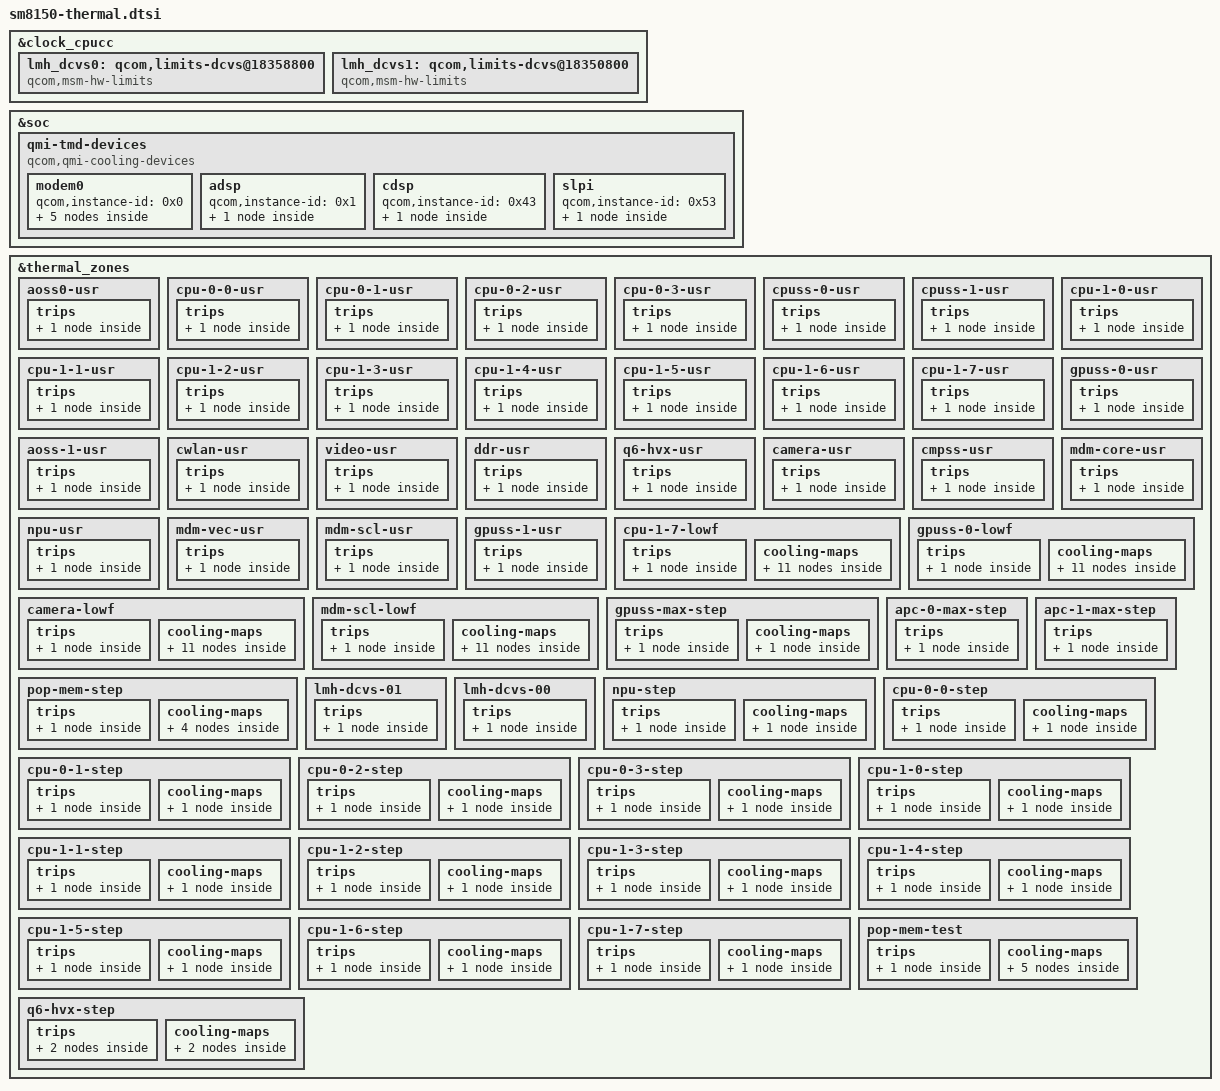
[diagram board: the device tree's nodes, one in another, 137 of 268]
/* Copyright (c) 2018, The Linux Foundation. All rights reserved.
 *
 * This program is free software; you can redistribute it and/or modify
 * it under the terms of the GNU General Public License version 2 and
 * only version 2 as published by the Free Software Foundation.
 *
 * This program is distributed in the hope that it will be useful,
 * but WITHOUT ANY WARRANTY; without even the implied warranty of
 * MERCHANTABILITY or FITNESS FOR A PARTICULAR PURPOSE.  See the
 * GNU General Public License for more details.
 */

#include <dt-bindings/thermal/thermal.h>

&clock_cpucc {
	#address-cells = <1>;
	#size-cells = <1>;
	lmh_dcvs0: qcom,limits-dcvs@18358800 {
		compatible = "qcom,msm-hw-limits";
		interrupts = <GIC_SPI 32 IRQ_TYPE_LEVEL_HIGH>;
		qcom,affinity = <0>;
		reg = <0x18358800 0x1000>,
			<0x18323000 0x1000>;
		#thermal-sensor-cells = <0>;
	};

	lmh_dcvs1: qcom,limits-dcvs@18350800 {
		compatible = "qcom,msm-hw-limits";
		interrupts = <GIC_SPI 33 IRQ_TYPE_LEVEL_HIGH>;
		qcom,affinity = <1>;
		reg = <0x18350800 0x1000>,
			<0x18325800 0x1000>;
		#thermal-sensor-cells = <0>;
		isens_vref_0p8-supply = <&pm8150_l5_ao>;
		isens-vref-0p8-settings = <880000 880000 20000>;
		isens_vref_1p8-supply = <&pm8150_l12_ao>;
		isens-vref-1p8-settings = <1800000 1800000 20000>;
	};
};

&soc {
	qmi-tmd-devices {
		compatible = "qcom,qmi-cooling-devices";

		modem0 {
			qcom,instance-id = <0x0>;

			modem0_pa: modem0_pa {
				qcom,qmi-dev-name = "pa";
				#cooling-cells = <2>;
			};

			modem0_proc: modem0_proc {
				qcom,qmi-dev-name = "modem";
				#cooling-cells = <2>;
			};

			modem0_current: modem0_current {
				qcom,qmi-dev-name = "modem_current";
				#cooling-cells = <2>;
			};

			modem0_skin: modem0_skin {
				qcom,qmi-dev-name = "modem_skin";
				#cooling-cells = <2>;
			};

			modem0_vdd: modem0_vdd {
				qcom,qmi-dev-name = "cpuv_restriction_cold";
				#cooling-cells = <2>;
			};
		};

		adsp {
			qcom,instance-id = <0x1>;

			adsp_vdd: adsp_vdd {
				qcom,qmi-dev-name = "cpuv_restriction_cold";
				#cooling-cells = <2>;
			};
		};

		cdsp {
			qcom,instance-id = <0x43>;

			cdsp_vdd: cdsp_vdd {
				qcom,qmi-dev-name = "cpuv_restriction_cold";
				#cooling-cells = <2>;
			};
		};

		slpi {
			qcom,instance-id = <0x53>;

			slpi_vdd: slpi_vdd {
				qcom,qmi-dev-name = "cpuv_restriction_cold";
				#cooling-cells = <2>;
			};
		};
	};
};

&thermal_zones {
	aoss0-usr {
		polling-delay-passive = <0>;
		polling-delay = <0>;
		thermal-governor = "user_space";
		thermal-sensors = <&tsens0 0>;
		trips {
			active-config0 {
				temperature = <125000>;
				hysteresis = <1000>;
				type = "passive";
			};
		};
	};

	cpu-0-0-usr {
		polling-delay-passive = <0>;
		polling-delay = <0>;
		thermal-governor = "user_space";
		thermal-sensors = <&tsens0 1>;
		trips {
			active-config0 {
				temperature = <125000>;
				hysteresis = <1000>;
				type = "passive";
			};
		};
	};

	cpu-0-1-usr {
		polling-delay-passive = <0>;
		polling-delay = <0>;
		thermal-governor = "user_space";
		thermal-sensors = <&tsens0 2>;
		trips {
			active-config0 {
				temperature = <125000>;
				hysteresis = <1000>;
				type = "passive";
			};
		};
	};

	cpu-0-2-usr {
		polling-delay-passive = <0>;
		polling-delay = <0>;
		thermal-governor = "user_space";
		thermal-sensors = <&tsens0 3>;
		trips {
			active-config0 {
				temperature = <125000>;
				hysteresis = <1000>;
				type = "passive";
			};
		};
	};

	cpu-0-3-usr {
		polling-delay-passive = <0>;
		polling-delay = <0>;
		thermal-sensors = <&tsens0 4>;
		thermal-governor = "user_space";
		trips {
			active-config0 {
				temperature = <125000>;
				hysteresis = <1000>;
				type = "passive";
			};
		};
	};

	cpuss-0-usr {
		polling-delay-passive = <0>;
		polling-delay = <0>;
		thermal-sensors = <&tsens0 5>;
		thermal-governor = "user_space";
		trips {
			active-config0 {
				temperature = <125000>;
				hysteresis = <1000>;
				type = "passive";
			};
		};
	};

	cpuss-1-usr {
		polling-delay-passive = <0>;
		polling-delay = <0>;
		thermal-sensors = <&tsens0 6>;
		thermal-governor = "user_space";
		trips {
			active-config0 {
				temperature = <125000>;
				hysteresis = <1000>;
				type = "passive";
			};
		};
	};

	cpu-1-0-usr {
		polling-delay-passive = <0>;
		polling-delay = <0>;
		thermal-sensors = <&tsens0 7>;
		thermal-governor = "user_space";
		trips {
			active-config0 {
				temperature = <125000>;
				hysteresis = <1000>;
				type = "passive";
			};
		};
	};

	cpu-1-1-usr {
		polling-delay-passive = <0>;
		polling-delay = <0>;
		thermal-sensors = <&tsens0 8>;
		thermal-governor = "user_space";
		trips {
			active-config0 {
				temperature = <125000>;
				hysteresis = <1000>;
				type = "passive";
			};
		};
	};

	cpu-1-2-usr {
		polling-delay-passive = <0>;
		polling-delay = <0>;
		thermal-sensors = <&tsens0 9>;
		thermal-governor = "user_space";
		trips {
			active-config0 {
				temperature = <125000>;
				hysteresis = <1000>;
				type = "passive";
			};
		};
	};

	cpu-1-3-usr {
		polling-delay-passive = <0>;
		polling-delay = <0>;
		thermal-sensors = <&tsens0 10>;
		thermal-governor = "user_space";
		trips {
			active-config0 {
				temperature = <125000>;
				hysteresis = <1000>;
				type = "passive";
			};
		};
	};

	cpu-1-4-usr {
		polling-delay-passive = <0>;
		polling-delay = <0>;
		thermal-sensors = <&tsens0 11>;
		thermal-governor = "user_space";
		trips {
			active-config0 {
				temperature = <125000>;
				hysteresis = <1000>;
				type = "passive";
			};
		};
	};

	cpu-1-5-usr {
		polling-delay-passive = <0>;
		polling-delay = <0>;
		thermal-sensors = <&tsens0 12>;
		thermal-governor = "user_space";
		trips {
			active-config0 {
				temperature = <125000>;
				hysteresis = <1000>;
				type = "passive";
			};
		};
	};

	cpu-1-6-usr {
		polling-delay-passive = <0>;
		polling-delay = <0>;
		thermal-sensors = <&tsens0 13>;
		thermal-governor = "user_space";
		trips {
			active-config0 {
				temperature = <125000>;
				hysteresis = <1000>;
				type = "passive";
			};
		};
	};

	cpu-1-7-usr {
		polling-delay-passive = <0>;
		polling-delay = <0>;
		thermal-sensors = <&tsens0 14>;
		thermal-governor = "user_space";
		trips {
			active-config0 {
				temperature = <125000>;
				hysteresis = <1000>;
				type = "passive";
			};
		};
	};

	gpuss-0-usr {
		polling-delay-passive = <0>;
		polling-delay = <0>;
		thermal-sensors = <&tsens0 15>;
		thermal-governor = "user_space";
		trips {
			active-config0 {
				temperature = <125000>;
				hysteresis = <1000>;
				type = "passive";
			};
		};
	};

	aoss-1-usr {
		polling-delay-passive = <0>;
		polling-delay = <0>;
		thermal-sensors = <&tsens1 0>;
		thermal-governor = "user_space";
		trips {
			active-config0 {
				temperature = <125000>;
				hysteresis = <1000>;
				type = "passive";
			};
		};
	};

	cwlan-usr {
		polling-delay-passive = <0>;
		polling-delay = <0>;
		thermal-sensors = <&tsens1 1>;
		thermal-governor = "user_space";
		trips {
			active-config0 {
				temperature = <125000>;
				hysteresis = <1000>;
				type = "passive";
			};
		};
	};

	video-usr {
		polling-delay-passive = <0>;
		polling-delay = <0>;
		thermal-sensors = <&tsens1 2>;
		thermal-governor = "user_space";
		trips {
			active-config0 {
				temperature = <125000>;
				hysteresis = <1000>;
				type = "passive";
			};
		};
	};

	ddr-usr {
		polling-delay-passive = <0>;
		polling-delay = <0>;
		thermal-sensors = <&tsens1 3>;
		thermal-governor = "user_space";
		trips {
			active-config0 {
				temperature = <125000>;
				hysteresis = <1000>;
				type = "passive";
			};
		};
	};

	q6-hvx-usr {
		polling-delay-passive = <0>;
		polling-delay = <0>;
		thermal-sensors = <&tsens1 4>;
		thermal-governor = "user_space";
		trips {
			active-config0 {
				temperature = <125000>;
				hysteresis = <1000>;
				type = "passive";
			};
		};
	};

	camera-usr {
		polling-delay-passive = <0>;
		polling-delay = <0>;
		thermal-sensors = <&tsens1 5>;
		thermal-governor = "user_space";
		trips {
			active-config0 {
				temperature = <125000>;
				hysteresis = <1000>;
				type = "passive";
			};
		};
	};

	cmpss-usr {
		polling-delay-passive = <0>;
		polling-delay = <0>;
		thermal-sensors = <&tsens1 6>;
		thermal-governor = "user_space";
		trips {
			active-config0 {
				temperature = <125000>;
				hysteresis = <1000>;
				type = "passive";
			};
		};
	};

	mdm-core-usr {
		polling-delay-passive = <0>;
		polling-delay = <0>;
		thermal-sensors = <&tsens1 7>;
		thermal-governor = "user_space";
		trips {
			active-config0 {
				temperature = <125000>;
				hysteresis = <1000>;
				type = "passive";
			};
		};
	};

	npu-usr {
		polling-delay-passive = <0>;
		polling-delay = <0>;
		thermal-sensors = <&tsens1 8>;
		thermal-governor = "user_space";
		trips {
			active-config0 {
				temperature = <125000>;
				hysteresis = <1000>;
				type = "passive";
			};
		};
	};

	mdm-vec-usr {
		polling-delay-passive = <0>;
		polling-delay = <0>;
		thermal-sensors = <&tsens1 9>;
		thermal-governor = "user_space";
		trips {
			active-config0 {
				temperature = <125000>;
				hysteresis = <1000>;
				type = "passive";
			};
		};
	};

	mdm-scl-usr {
		polling-delay-passive = <0>;
		polling-delay = <0>;
		thermal-sensors = <&tsens1 10>;
		thermal-governor = "user_space";
		trips {
			active-config0 {
				temperature = <125000>;
				hysteresis = <1000>;
				type = "passive";
			};
		};
	};

	gpuss-1-usr {
		polling-delay-passive = <0>;
		polling-delay = <0>;
		thermal-governor = "user_space";
		thermal-sensors = <&tsens1 11>;
		trips {
			active-config0 {
				temperature = <125000>;
				hysteresis = <1000>;
				type = "passive";
			};
		};
	};

	cpu-1-7-lowf {
		polling-delay-passive = <0>;
		polling-delay = <0>;
		thermal-sensors = <&tsens0 14>;
		thermal-governor = "low_limits_floor";
		tracks-low;
		trips {
			cpu17_trip: cpu17-trip {
				temperature = <5000>;
				hysteresis = <5000>;
				type = "passive";
			};
		};
		cooling-maps {
			cpu0_cdev {
				trip = <&cpu17_trip>;
				cooling-device = <&CPU0 1 1>;
			};
			cpu1_cdev {
				trip = <&cpu17_trip>;
				cooling-device = <&CPU4 5 5>;
			};
			cx_vdd_cdev {
				trip = <&cpu17_trip>;
				cooling-device = <&cx_cdev 0 0>;
			};
			mx_vdd_cdev {
				trip = <&cpu17_trip>;
				cooling-device = <&mx_cdev 0 0>;
			};
			ebi_vdd_cdev {
				trip = <&cpu17_trip>;
				cooling-device = <&ebi_cdev 0 0>;
			};
			mmcx_vdd_cdev {
				trip = <&cpu17_trip>;
				cooling-device = <&mm_cx_cdev 0 0>;
			};
			modem_vdd_cdev {
				trip = <&cpu17_trip>;
				cooling-device = <&modem0_vdd 0 0>;
			};
			adsp_vdd_cdev {
				trip = <&cpu17_trip>;
				cooling-device = <&adsp_vdd 0 0>;
			};
			cdsp_vdd_cdev {
				trip = <&cpu17_trip>;
				cooling-device = <&cdsp_vdd 0 0>;
			};
			slpi_vdd_cdev {
				trip = <&cpu17_trip>;
				cooling-device = <&slpi_vdd 0 0>;
			};
			gpu_vdd_cdev {
				trip = <&cpu17_trip>;
				cooling-device = <&msm_gpu (THERMAL_MAX_LIMIT-2)
							(THERMAL_MAX_LIMIT-2)>;
			};
		};
	};

	gpuss-0-lowf {
		polling-delay-passive = <0>;
		polling-delay = <0>;
		thermal-sensors = <&tsens0 15>;
		thermal-governor = "low_limits_floor";
		tracks-low;
		trips {
			gpuss0_trip: gpuss0-trip {
				temperature = <5000>;
				hysteresis = <5000>;
				type = "passive";
			};
		};
		cooling-maps {
			cpu0_cdev {
				trip = <&gpuss0_trip>;
				cooling-device = <&CPU0 1 1>;
			};
			cpu1_cdev {
				trip = <&gpuss0_trip>;
				cooling-device = <&CPU4 5 5>;
			};
			cx_vdd_cdev {
				trip = <&gpuss0_trip>;
				cooling-device = <&cx_cdev 0 0>;
			};
			mx_vdd_cdev {
				trip = <&gpuss0_trip>;
				cooling-device = <&mx_cdev 0 0>;
			};
			ebi_vdd_cdev {
				trip = <&gpuss0_trip>;
				cooling-device = <&ebi_cdev 0 0>;
			};
			mmcx_vdd_cdev {
				trip = <&gpuss0_trip>;
				cooling-device = <&mm_cx_cdev 0 0>;
			};
			modem_vdd_cdev {
				trip = <&gpuss0_trip>;
				cooling-device = <&modem0_vdd 0 0>;
			};
			adsp_vdd_cdev {
				trip = <&gpuss0_trip>;
				cooling-device = <&adsp_vdd 0 0>;
			};
			cdsp_vdd_cdev {
				trip = <&gpuss0_trip>;
				cooling-device = <&cdsp_vdd 0 0>;
			};
			slpi_vdd_cdev {
				trip = <&gpuss0_trip>;
				cooling-device = <&slpi_vdd 0 0>;
			};
			gpu_vdd_cdev {
				trip = <&gpuss0_trip>;
				cooling-device = <&msm_gpu (THERMAL_MAX_LIMIT-2)
							(THERMAL_MAX_LIMIT-2)>;
			};
		};
	};

	camera-lowf {
		polling-delay-passive = <0>;
		polling-delay = <0>;
		thermal-sensors = <&tsens1 5>;
		thermal-governor = "low_limits_floor";
		tracks-low;
		trips {
			camera_trip: camera-trip {
				temperature = <5000>;
				hysteresis = <5000>;
				type = "passive";
			};
		};
		cooling-maps {
			cpu0_cdev {
				trip = <&camera_trip>;
				cooling-device = <&CPU0 1 1>;
			};
			cpu1_cdev {
				trip = <&camera_trip>;
				cooling-device = <&CPU4 5 5>;
			};
			cx_vdd_cdev {
				trip = <&camera_trip>;
				cooling-device = <&cx_cdev 0 0>;
			};
			mx_vdd_cdev {
				trip = <&camera_trip>;
				cooling-device = <&mx_cdev 0 0>;
			};
			ebi_vdd_cdev {
				trip = <&camera_trip>;
				cooling-device = <&ebi_cdev 0 0>;
			};
			mmcx_vdd_cdev {
				trip = <&camera_trip>;
				cooling-device = <&mm_cx_cdev 0 0>;
			};
			modem_vdd_cdev {
				trip = <&camera_trip>;
				cooling-device = <&modem0_vdd 0 0>;
			};
			adsp_vdd_cdev {
				trip = <&camera_trip>;
				cooling-device = <&adsp_vdd 0 0>;
			};
			cdsp_vdd_cdev {
				trip = <&camera_trip>;
				cooling-device = <&cdsp_vdd 0 0>;
			};
			slpi_vdd_cdev {
				trip = <&camera_trip>;
				cooling-device = <&slpi_vdd 0 0>;
			};
			gpu_vdd_cdev {
				trip = <&camera_trip>;
				cooling-device = <&msm_gpu (THERMAL_MAX_LIMIT-2)
							(THERMAL_MAX_LIMIT-2)>;
			};
		};
	};

	mdm-scl-lowf {
		polling-delay-passive = <0>;
		polling-delay = <0>;
		thermal-sensors = <&tsens1 10>;
		thermal-governor = "low_limits_floor";
		tracks-low;
		trips {
			mdms_trip: mdms-trip {
				temperature = <5000>;
				hysteresis = <5000>;
				type = "passive";
			};
		};
		cooling-maps {
			cpu0_cdev {
				trip = <&mdms_trip>;
				cooling-device = <&CPU0 1 1>;
			};
			cpu1_cdev {
				trip = <&mdms_trip>;
				cooling-device = <&CPU4 5 5>;
			};
			cx_vdd_cdev {
				trip = <&mdms_trip>;
				cooling-device = <&cx_cdev 0 0>;
			};
			mx_vdd_cdev {
				trip = <&mdms_trip>;
				cooling-device = <&mx_cdev 0 0>;
			};
			ebi_vdd_cdev {
				trip = <&mdms_trip>;
				cooling-device = <&ebi_cdev 0 0>;
			};
			mmcx_vdd_cdev {
				trip = <&mdms_trip>;
				cooling-device = <&mm_cx_cdev 0 0>;
			};
			modem_vdd_cdev {
				trip = <&mdms_trip>;
				cooling-device = <&modem0_vdd 0 0>;
			};
			adsp_vdd_cdev {
				trip = <&mdms_trip>;
				cooling-device = <&adsp_vdd 0 0>;
			};
			cdsp_vdd_cdev {
				trip = <&mdms_trip>;
				cooling-device = <&cdsp_vdd 0 0>;
			};
			slpi_vdd_cdev {
				trip = <&mdms_trip>;
				cooling-device = <&slpi_vdd 0 0>;
			};
			gpu_vdd_cdev {
				trip = <&mdms_trip>;
				cooling-device = <&msm_gpu (THERMAL_MAX_LIMIT-2)
							(THERMAL_MAX_LIMIT-2)>;
			};
		};
	};

	gpuss-max-step {
		polling-delay-passive = <10>;
		polling-delay = <100>;
		thermal-governor = "step_wise";
		trips {
			gpu_trip0: gpu-trip0 {
				temperature = <95000>;
				hysteresis = <0>;
				type = "passive";
			};
		};
		cooling-maps {
			gpu_cdev {
				trip = <&gpu_trip0>;
				cooling-device = <&msm_gpu THERMAL_NO_LIMIT
							THERMAL_NO_LIMIT>;
			};
		};
	};

	apc-0-max-step {
		polling-delay-passive = <0>;
		polling-delay = <0>;
		thermal-governor = "step_wise";
		trips {
			silver-trip {
				temperature = <120000>;
				hysteresis = <0>;
				type = "passive";
			};
		};
	};

	apc-1-max-step {
		polling-delay-passive = <0>;
		polling-delay = <0>;
		thermal-governor = "step_wise";
		trips {
			gold-trip {
				temperature = <120000>;
				hysteresis = <0>;
				type = "passive";
			};
		};
	};

	pop-mem-step {
		polling-delay-passive = <10>;
		polling-delay = <0>;
		thermal-sensors = <&tsens1 3>;
		thermal-governor = "step_wise";
		trips {
			pop_trip: pop-trip {
				temperature = <95000>;
				hysteresis = <0>;
				type = "passive";
			};
		};
		cooling-maps {
			pop_cdev4 {
				trip = <&pop_trip>;
				cooling-device =
					<&CPU4 THERMAL_NO_LIMIT
						(THERMAL_MAX_LIMIT-1)>;
			};
			pop_cdev5 {
				trip = <&pop_trip>;
				cooling-device =
					<&CPU5 THERMAL_NO_LIMIT
						(THERMAL_MAX_LIMIT-1)>;
			};
			pop_cdev6 {
				trip = <&pop_trip>;
				cooling-device =
					<&CPU6 THERMAL_NO_LIMIT
						(THERMAL_MAX_LIMIT-1)>;
			};
			pop_cdev7 {
				trip = <&pop_trip>;
				cooling-device =
					<&CPU7 THERMAL_NO_LIMIT
						(THERMAL_MAX_LIMIT-1)>;
			};
		};
	};

	lmh-dcvs-01 {
		polling-delay-passive = <0>;
		polling-delay = <0>;
		thermal-governor = "user_space";
		thermal-sensors = <&lmh_dcvs1>;

		trips {
			active-config {
				temperature = <85000>;
				hysteresis = <25000>;
				type = "passive";
			};
		};
	};

	lmh-dcvs-00 {
		polling-delay-passive = <0>;
		polling-delay = <0>;
		thermal-governor = "user_space";
		thermal-sensors = <&lmh_dcvs0>;

		trips {
			active-config {
				temperature = <85000>;
				hysteresis = <25000>;
				type = "passive";
			};
		};
	};

	npu-step {
		polling-delay-passive = <10>;
		polling-delay = <0>;
		thermal-sensors = <&tsens1 8>;
		thermal-governor = "step_wise";
		trips {
			npu_trip0: npu-trip0 {
				temperature = <95000>;
				hysteresis = <0>;
				type = "passive";
			};
		};
		cooling-maps {
			npu_cdev {
				trip = <&npu_trip0>;
				cooling-device =
					<&msm_npu THERMAL_NO_LIMIT
						THERMAL_NO_LIMIT>;
			};
		};
	};

	cpu-0-0-step {
		polling-delay-passive = <0>;
		polling-delay = <0>;
		thermal-governor = "step_wise";
		thermal-sensors = <&tsens0 1>;
		trips {
			cpu00_config: cpu00-config {
				temperature = <110000>;
				hysteresis = <10000>;
				type = "passive";
			};
		};
		cooling-maps {
			cpu00_cdev {
				trip = <&cpu00_config>;
				cooling-device =
					<&CPU0 THERMAL_MAX_LIMIT
						THERMAL_MAX_LIMIT>;
			};
		};
	};

	cpu-0-1-step {
		polling-delay-passive = <0>;
		polling-delay = <0>;
		thermal-governor = "step_wise";
		thermal-sensors = <&tsens0 2>;
		trips {
			cpu01_config: cpu01-config {
				temperature = <110000>;
				hysteresis = <10000>;
				type = "passive";
			};
		};
		cooling-maps {
			cpu01_cdev {
				trip = <&cpu01_config>;
				cooling-device =
					<&CPU1 THERMAL_MAX_LIMIT
						THERMAL_MAX_LIMIT>;
			};
		};
	};

	cpu-0-2-step {
		polling-delay-passive = <0>;
		polling-delay = <0>;
		thermal-governor = "step_wise";
		thermal-sensors = <&tsens0 3>;
		trips {
			cpu02_config: cpu02-config {
				temperature = <110000>;
				hysteresis = <10000>;
				type = "passive";
			};
		};
		cooling-maps {
			cpu02_cdev {
				trip = <&cpu02_config>;
				cooling-device =
					<&CPU2 THERMAL_MAX_LIMIT
						THERMAL_MAX_LIMIT>;
			};
		};
	};

	cpu-0-3-step {
		polling-delay-passive = <0>;
		polling-delay = <0>;
		thermal-sensors = <&tsens0 4>;
		thermal-governor = "step_wise";
		trips {
			cpu03_config: cpu03-config {
				temperature = <110000>;
				hysteresis = <10000>;
				type = "passive";
			};
		};
		cooling-maps {
			cpu03_cdev {
				trip = <&cpu03_config>;
				cooling-device =
					<&CPU3 THERMAL_MAX_LIMIT
						THERMAL_MAX_LIMIT>;
			};
		};
	};

	cpu-1-0-step {
		polling-delay-passive = <0>;
		polling-delay = <0>;
		thermal-sensors = <&tsens0 7>;
		thermal-governor = "step_wise";
		trips {
			cpu10_config: cpu10-config {
				temperature = <110000>;
				hysteresis = <10000>;
				type = "passive";
			};
		};
		cooling-maps {
			cpu10_cdev {
				trip = <&cpu10_config>;
				cooling-device =
					<&CPU4 THERMAL_MAX_LIMIT
						THERMAL_MAX_LIMIT>;
			};
		};
	};

	cpu-1-1-step {
		polling-delay-passive = <0>;
		polling-delay = <0>;
		thermal-sensors = <&tsens0 8>;
		thermal-governor = "step_wise";
		trips {
			cpu11_config: cpu11-config {
				temperature = <110000>;
				hysteresis = <10000>;
				type = "passive";
			};
		};
		cooling-maps {
			cpu11_cdev {
				trip = <&cpu11_config>;
				cooling-device =
					<&CPU5 THERMAL_MAX_LIMIT
						THERMAL_MAX_LIMIT>;
			};
		};
	};

	cpu-1-2-step {
		polling-delay-passive = <0>;
		polling-delay = <0>;
		thermal-sensors = <&tsens0 9>;
		thermal-governor = "step_wise";
		trips {
			cpu12_config: cpu12-config {
				temperature = <110000>;
				hysteresis = <10000>;
				type = "passive";
			};
		};
		cooling-maps {
			cpu12_cdev {
				trip = <&cpu12_config>;
				cooling-device =
					<&CPU6 THERMAL_MAX_LIMIT
						THERMAL_MAX_LIMIT>;
			};
		};
	};

	cpu-1-3-step {
		polling-delay-passive = <0>;
		polling-delay = <0>;
		thermal-sensors = <&tsens0 10>;
		thermal-governor = "step_wise";
		trips {
			cpu13_config: cpu13-config {
				temperature = <110000>;
				hysteresis = <10000>;
				type = "passive";
			};
		};
		cooling-maps {
			cpu13_cdev {
				trip = <&cpu13_config>;
				cooling-device =
					<&CPU7 THERMAL_MAX_LIMIT
						THERMAL_MAX_LIMIT>;
			};
		};
	};

	cpu-1-4-step {
		polling-delay-passive = <0>;
		polling-delay = <0>;
		thermal-sensors = <&tsens0 11>;
		thermal-governor = "step_wise";
		trips {
			cpu14_config: cpu14-config {
				temperature = <110000>;
				hysteresis = <10000>;
				type = "passive";
			};
		};
		cooling-maps {
			cpu14_cdev {
				trip = <&cpu14_config>;
				cooling-device =
					<&CPU4 THERMAL_MAX_LIMIT
						THERMAL_MAX_LIMIT>;
			};
		};
	};

	cpu-1-5-step {
		polling-delay-passive = <0>;
		polling-delay = <0>;
		thermal-sensors = <&tsens0 12>;
		thermal-governor = "step_wise";
		trips {
			cpu15_config: cpu15-config {
				temperature = <110000>;
				hysteresis = <10000>;
				type = "passive";
			};
		};
		cooling-maps {
			cpu15_cdev {
				trip = <&cpu15_config>;
				cooling-device =
					<&CPU5 THERMAL_MAX_LIMIT
						THERMAL_MAX_LIMIT>;
			};
		};
	};

	cpu-1-6-step {
		polling-delay-passive = <0>;
		polling-delay = <0>;
		thermal-sensors = <&tsens0 13>;
		thermal-governor = "step_wise";
		trips {
			cpu16_config: cpu16-config {
				temperature = <110000>;
				hysteresis = <10000>;
				type = "passive";
			};
		};
		cooling-maps {
			cpu16_cdev {
				trip = <&cpu16_config>;
				cooling-device =
					<&CPU6 THERMAL_MAX_LIMIT
						THERMAL_MAX_LIMIT>;
			};
		};
	};

	cpu-1-7-step {
		polling-delay-passive = <0>;
		polling-delay = <0>;
		thermal-sensors = <&tsens0 14>;
		thermal-governor = "step_wise";
		trips {
			cpu17_config: cpu17-config {
				temperature = <110000>;
				hysteresis = <10000>;
				type = "passive";
			};
		};
		cooling-maps {
			cpu17_cdev {
				trip = <&cpu17_config>;
				cooling-device =
					<&CPU7 THERMAL_MAX_LIMIT
						THERMAL_MAX_LIMIT>;
			};
		};
	};

	pop-mem-test {
		polling-delay-passive = <10>;
		polling-delay = <0>;
		thermal-sensors = <&tsens1 3>;
		thermal-governor = "step_wise";
		trips {
			pop_test_trip: pop-test-trip {
				temperature = <125000>;
				hysteresis = <0>;
				type = "passive";
			};
		};
		cooling-maps {
			pop_test_cdev0 {
				trip = <&pop_test_trip>;
				cooling-device =
					<&modem0_pa THERMAL_NO_LIMIT
						THERMAL_NO_LIMIT>;
			};
			pop_test_cdev1 {
				trip = <&pop_test_trip>;
				cooling-device =
					<&modem0_proc THERMAL_NO_LIMIT
						THERMAL_NO_LIMIT>;
			};
			pop_test_cdev2 {
				trip = <&pop_test_trip>;
				cooling-device =
					<&modem0_current THERMAL_NO_LIMIT
						THERMAL_NO_LIMIT>;
			};
			pop_test_cdev3 {
				trip = <&pop_test_trip>;
				cooling-device =
					<&modem0_skin THERMAL_NO_LIMIT
						THERMAL_NO_LIMIT>;
			};
			pop_test_cdev4 {
				trip = <&pop_test_trip>;
				cooling-device =
					<&mdss_mdp THERMAL_NO_LIMIT
						THERMAL_NO_LIMIT>;
			};
		};
	};

	q6-hvx-step {
		polling-delay-passive = <10>;
		polling-delay = <0>;
		thermal-sensors = <&tsens1 4>;
		thermal-governor = "step_wise";
		trips {
			q6_hvx_step0: q6-hvx-step0 {
				temperature = <95000>;
				hysteresis = <0>;
				type = "passive";
			};
			q6_hvx_step1: q6-hvx-step1 {
				temperature = <105000>;
				hysteresis = <5000>;
				type = "passive";
			};
		};
		cooling-maps {
			hvx_cdev_lvl0 {
				trip = <&q6_hvx_step0>;
				cooling-device = <&msm_cdsp_rm
						THERMAL_NO_LIMIT 6>;
			};
			hvx_cdev_lvl1 {
				trip = <&q6_hvx_step1>;
				cooling-device = <&msm_cdsp_rm 6 6>;
			};
		};
	};
};
